# USB3SS0_PHY2 register map
Vendor: Texas Instruments
Peripheral module from a debugger description file (folder am65x).
Registers are 32-bit, access per field, reset values left out (the file's numbers can be read two ways) unless marked. A register's access mark holds for its fields unless they carry their own. Offsets are as the file gives them; lines under a group give offsets from that group; [hi:lo] are bit positions; {n}, {i} and the like mark numbered series; 'fields as' and 'values as' point back to an identical list; <NAME> marks a mode.

## USB3SS0_PHY2
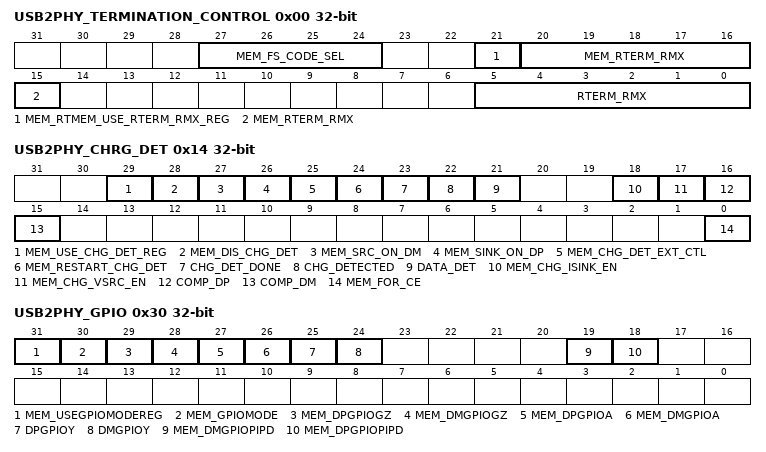
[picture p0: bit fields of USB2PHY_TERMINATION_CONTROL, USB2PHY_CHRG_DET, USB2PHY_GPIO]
0x00 USB2PHY_TERMINATION_CONTROL — Contains bits related to control of terminations in USB2PHY
  [27:24] MEM_FS_CODE_SEL rw — FS Code selection control
  [21] MEM_RTMEM_USE_RTERM_RMX_REG rw — Override termination resistor trim code with mem_RTERM_RMX from this register
  [20:15] MEM_RTERM_RMX rw — The value written to this field is used as Termination resistor trim code if bit 21 is set to 1. BMEM_USE_RTERM_RMX_REG is set to 1. Can be used to improve the HS eye diagram by reducing the termination resistance. Increase the value until eye passes. Also ensure receiver compliance is also met.
  [5:0] RTERM_RMX ro — Returns the current value of RTERM_RMX
0x14 USB2PHY_CHRG_DET — This is the charger detect register. This register is not used in the dead battery case.
  [29] MEM_USE_CHG_DET_REG rw — Use bits 28-24 and 18-17 from this register
  [28] MEM_DIS_CHG_DET rw — When read, returns current value of charger detect input. When mem_USE_CHG_DET_REG = 1, the value written to this field overrides the corresponding charger detect input.
  [27] MEM_SRC_ON_DM rw
  [26] MEM_SINK_ON_DP rw — When read, returns current value of charger detect input. When mem_USE_CHG_DET_REG = 1, the value written to this field overrides the corresponding charger detect input.
  [25] MEM_CHG_DET_EXT_CTL rw — When read, returns current value of charger detect input. When mem_USE_CHG_DET_REG = 1, the value written to this field overrides the corresponding charger detect input.
  [24] MEM_RESTART_CHG_DET rw — Restart the charger detection protocol when this goes from 0 to 1
  [23] CHG_DET_DONE ro — Charger detect protocol has completed
  [22] CHG_DETECTED ro — Same signal as CE
  [21] DATA_DET ro — Output of the data det comparator
  [18] MEM_CHG_ISINK_EN rw — When read, returns current value of charger detect input. When mem_USE_CHG_DET_REG = 1, the value written to this field overrides the corresponding charger detect input.
  [17] MEM_CHG_VSRC_EN rw — When read, returns current value of charger detect input. When mem_USE_CHG_DET_REG = 1, the value written to this field overrides the corresponding charger detect input.
  [16] COMP_DP ro — Comparator on the DP line value
  [15] COMP_DM ro — Comparator on the DM line value
  [0] MEM_FOR_CE rw — Force CE = 1 when this bit is set
0x30 USB2PHY_GPIO — GPIO mode configurations and reads
  [31] MEM_USEGPIOMODEREG rw — When set to 1 use bits 31-24 from this register instead of primary inputs
  [30] MEM_GPIOMODE rw — Overrides the GPIO MODE primary input
  [29] MEM_DPGPIOGZ rw — Overrides the DP GPIO GZ primary input
  [28] MEM_DMGPIOGZ rw — Overrides the DM GPIO GZ primary input
  [27] MEM_DPGPIOA rw — Overrides the DP GPIO A primary input
  [26] MEM_DMGPIOA rw — Overrides the DM GPIO A primary input
  [25] DPGPIOY ro — DP GPIO Y output is stored here
  [24] DMGPIOY ro — DM GPIO Y output is stored here
  [19] MEM_DMGPIOPIPD rw — GPIO mode DM pull down enabled. Overrides the corresponding primary input
  [18] MEM_DPGPIOPIPD rw — GPIO mode DP pull-down enabled. Overrides the corresponding primary input.
0x48 USB2PHY_AD_INTERFACE_REG3 — All bits unless defined are bypass bits for internal analog to digital interface pins with the same name. All the bits of this register, except the over-ride bits return a 0 on read, if VDDLDO is off.
  [17:10] MEM_SPARE_IN_LDO rw — Depreciated. Use
0x4C USB2PHY_ANA_CONFIG1 rw — Used to configure and debug the analog blocks.
  [31] DISCON_DETECT_BYPASS — Disconnect detection window mode. 0x0: extends detection window for disconnect to the length of the SOF packet (not compliant with the USB2.0 spec). 0x1: limits the detection window for disconnect to last 8b of the SOF EOP (in compliance with the USB2.0 spec) to avoid incorrectly detecting a disconnect on boards with excessive reflections noise/ringing.
0x50 USB2PHY_ANA_CONFIG2 rw — Used to configure and debug the analog blocks.
  [19:15] MEM_FSRX_TEST
